# VPAC0_PAR_VPAC_VISS0_S_VBUSP_VISS_FCP_FCC_VBUSP_FLEXCC_S8B8 register map
Vendor: Texas Instruments
Peripheral module from a debugger description file (folder J7ES).
Registers are 32-bit, access per field, reset 0x0 unless marked. A register's access mark holds for its fields unless they carry their own. Offsets are as the file gives them; lines under a group give offsets from that group; [hi:lo] are bit positions; {n}, {i} and the like mark numbered series; 'fields as' and 'values as' point back to an identical list; <NAME> marks a mode.

## VPAC0_PAR_VPAC_VISS0_S_VBUSP_VISS_FCP_FCC_VBUSP_FLEXCC_S8B8
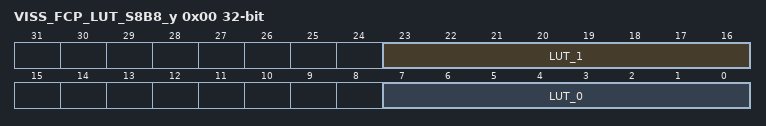
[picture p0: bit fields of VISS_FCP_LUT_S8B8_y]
0x00 VISS_FCP_LUT_S8B8_y — Memory for 12to8 LUT Offset = 00093000h + (y * 4h); where y = 0h to 100h
  [23:16] LUT_1 rw — Bank-1
  [7:0] LUT_0 rw — Bank-0
